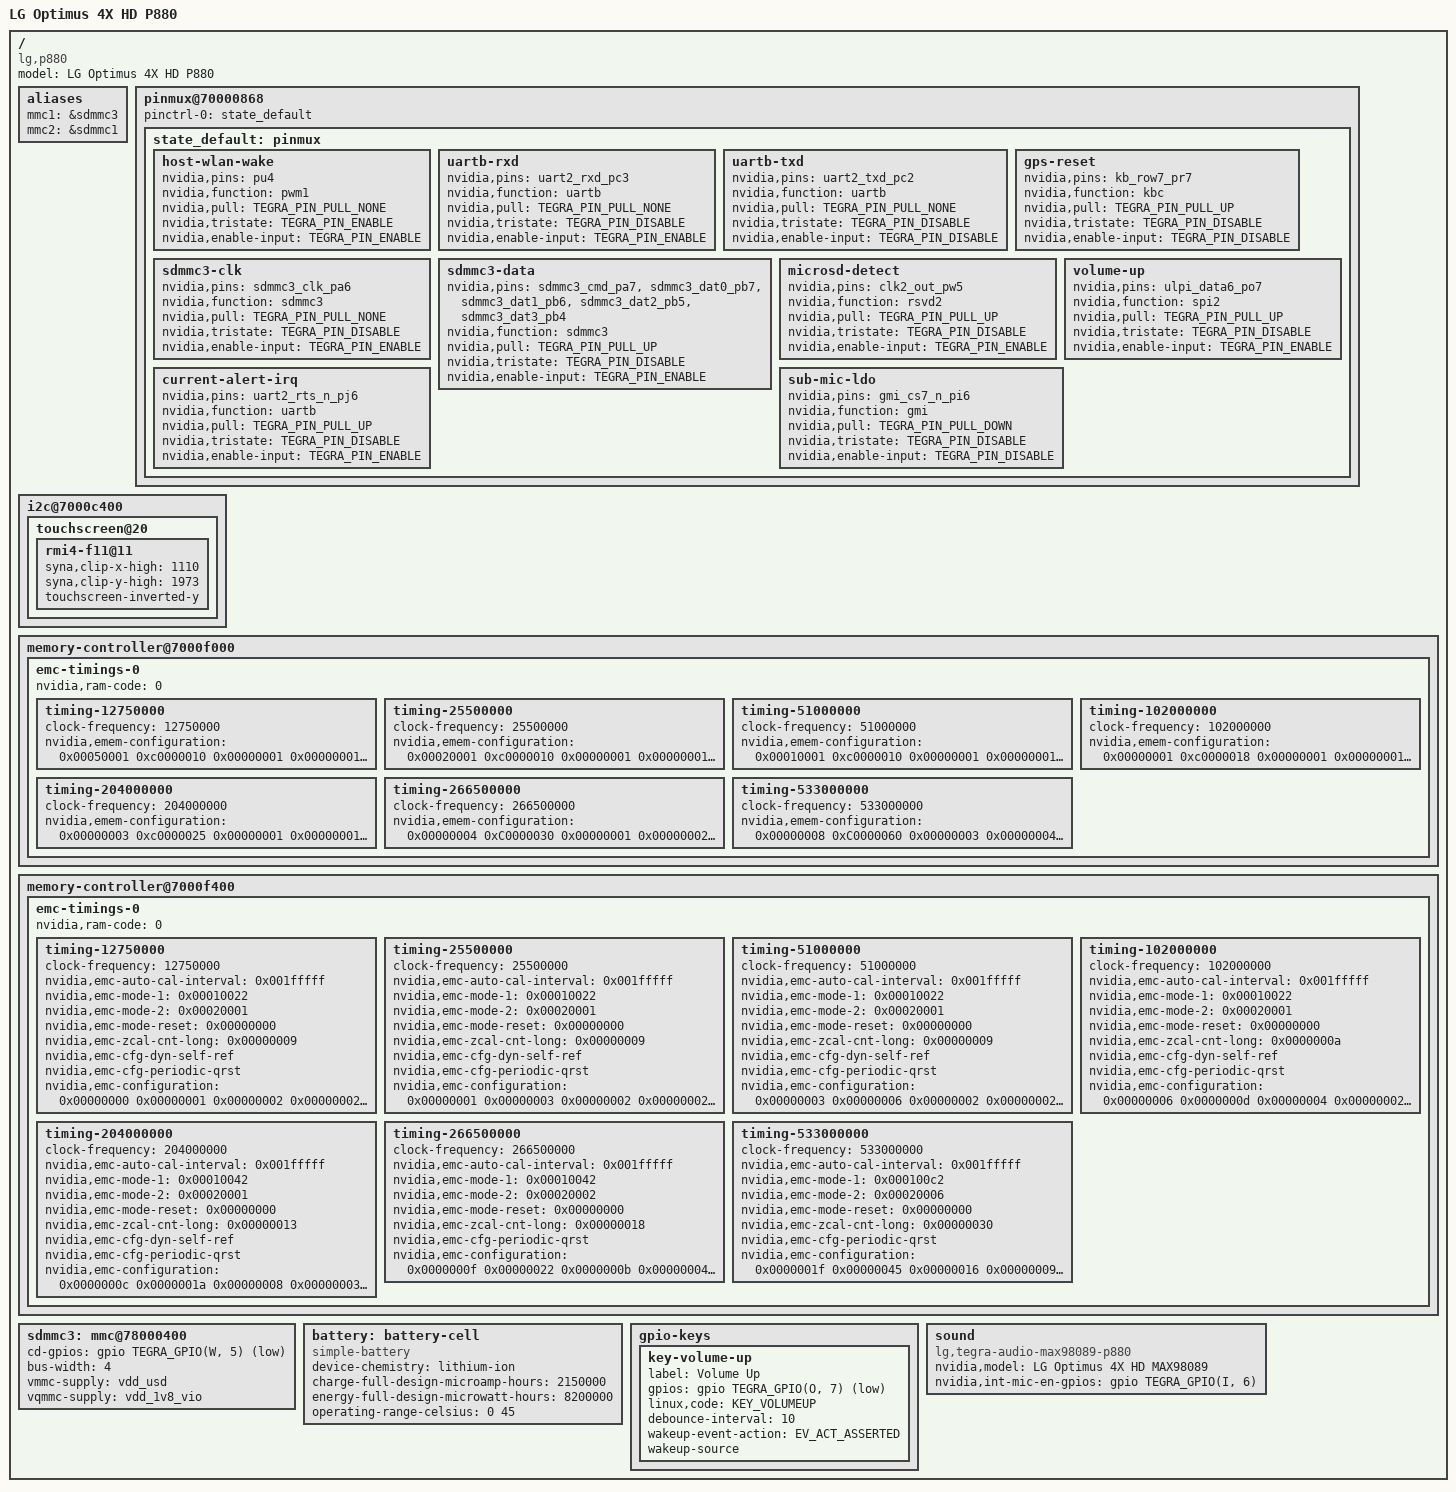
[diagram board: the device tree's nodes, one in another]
// SPDX-License-Identifier: GPL-2.0
/dts-v1/;

#include "tegra30-lg-x3.dtsi"

/ {
	model = "LG Optimus 4X HD P880";
	compatible = "lg,p880", "nvidia,tegra30";

	aliases {
		mmc1 = &sdmmc3; /* uSD slot */
		mmc2 = &sdmmc1; /* WiFi */
	};

	pinmux@70000868 {
		pinctrl-names = "default";
		pinctrl-0 = <&state_default>;

		state_default: pinmux {
			/* WLAN SDIO pinmux */
			host-wlan-wake {
				nvidia,pins = "pu4";
				nvidia,function = "pwm1";
				nvidia,pull = <TEGRA_PIN_PULL_NONE>;
				nvidia,tristate = <TEGRA_PIN_ENABLE>;
				nvidia,enable-input = <TEGRA_PIN_ENABLE>;
			};

			/* GNSS UART-B pinmux */
			uartb-rxd {
				nvidia,pins = "uart2_rxd_pc3";
				nvidia,function = "uartb";
				nvidia,pull = <TEGRA_PIN_PULL_NONE>;
				nvidia,tristate = <TEGRA_PIN_DISABLE>;
				nvidia,enable-input = <TEGRA_PIN_ENABLE>;
			};
			uartb-txd {
				nvidia,pins = "uart2_txd_pc2";
				nvidia,function = "uartb";
				nvidia,pull = <TEGRA_PIN_PULL_NONE>;
				nvidia,tristate = <TEGRA_PIN_DISABLE>;
				nvidia,enable-input = <TEGRA_PIN_DISABLE>;
			};
			gps-reset {
				nvidia,pins = "kb_row7_pr7";
				nvidia,function = "kbc";
				nvidia,pull = <TEGRA_PIN_PULL_UP>;
				nvidia,tristate = <TEGRA_PIN_DISABLE>;
				nvidia,enable-input = <TEGRA_PIN_DISABLE>;
			};

			/* MicroSD pinmux */
			sdmmc3-clk {
				nvidia,pins = "sdmmc3_clk_pa6";
				nvidia,function = "sdmmc3";
				nvidia,pull = <TEGRA_PIN_PULL_NONE>;
				nvidia,tristate = <TEGRA_PIN_DISABLE>;
				nvidia,enable-input = <TEGRA_PIN_ENABLE>;
			};
			sdmmc3-data {
				nvidia,pins = "sdmmc3_cmd_pa7",
						"sdmmc3_dat0_pb7",
						"sdmmc3_dat1_pb6",
						"sdmmc3_dat2_pb5",
						"sdmmc3_dat3_pb4";
				nvidia,function = "sdmmc3";
				nvidia,pull = <TEGRA_PIN_PULL_UP>;
				nvidia,tristate = <TEGRA_PIN_DISABLE>;
				nvidia,enable-input = <TEGRA_PIN_ENABLE>;
			};
			microsd-detect {
				nvidia,pins = "clk2_out_pw5";
				nvidia,function = "rsvd2";
				nvidia,pull = <TEGRA_PIN_PULL_UP>;
				nvidia,tristate = <TEGRA_PIN_DISABLE>;
				nvidia,enable-input = <TEGRA_PIN_ENABLE>;
			};

			/* GPIO keys pinmux */
			volume-up {
				nvidia,pins = "ulpi_data6_po7";
				nvidia,function = "spi2";
				nvidia,pull = <TEGRA_PIN_PULL_UP>;
				nvidia,tristate = <TEGRA_PIN_DISABLE>;
				nvidia,enable-input = <TEGRA_PIN_ENABLE>;
			};

			/* Sensors pinmux */
			current-alert-irq {
				nvidia,pins = "uart2_rts_n_pj6";
				nvidia,function = "uartb";
				nvidia,pull = <TEGRA_PIN_PULL_UP>;
				nvidia,tristate = <TEGRA_PIN_DISABLE>;
				nvidia,enable-input = <TEGRA_PIN_ENABLE>;
			};

			/* AUDIO pinmux */
			sub-mic-ldo {
				nvidia,pins = "gmi_cs7_n_pi6";
				nvidia,function = "gmi";
				nvidia,pull = <TEGRA_PIN_PULL_DOWN>;
				nvidia,tristate = <TEGRA_PIN_DISABLE>;
				nvidia,enable-input = <TEGRA_PIN_DISABLE>;
			};
		};
	};

	i2c@7000c400 {
		touchscreen@20 {
			rmi4-f11@11 {
				syna,clip-x-high = <1110>;
				syna,clip-y-high = <1973>;

				touchscreen-inverted-y;
			};
		};
	};

	memory-controller@7000f000 {
		emc-timings-0 {
			/* SAMSUNG 1GB K4P8G304EB FGC1 533MHz */
			nvidia,ram-code = <0>;

			timing-12750000 {
				clock-frequency = <12750000>;

				nvidia,emem-configuration = < 0x00050001 0xc0000010
					0x00000001 0x00000001 0x00000002 0x00000000
					0x00000003 0x00000001 0x00000002 0x00000004
					0x00000001 0x00000000 0x00000002 0x00000002
					0x02020001 0x00060402 0x77230303 0x001f0000 >;
			};

			timing-25500000 {
				clock-frequency = <25500000>;

				nvidia,emem-configuration = < 0x00020001 0xc0000010
					0x00000001 0x00000001 0x00000002 0x00000000
					0x00000003 0x00000001 0x00000002 0x00000004
					0x00000001 0x00000000 0x00000002 0x00000002
					0x02020001 0x00060402 0x73e30303 0x001f0000 >;
			};

			timing-51000000 {
				clock-frequency = <51000000>;

				nvidia,emem-configuration = < 0x00010001 0xc0000010
					0x00000001 0x00000001 0x00000002 0x00000000
					0x00000003 0x00000001 0x00000002 0x00000004
					0x00000001 0x00000000 0x00000002 0x00000002
					0x02020001 0x00060402 0x72c30303 0x001f0000 >;
			};

			timing-102000000 {
				clock-frequency = <102000000>;

				nvidia,emem-configuration = < 0x00000001 0xc0000018
					0x00000001 0x00000001 0x00000003 0x00000001
					0x00000003 0x00000001 0x00000002 0x00000004
					0x00000001 0x00000000 0x00000002 0x00000002
					0x02020001 0x00060403 0x72430504 0x001f0000 >;
			};

			timing-204000000 {
				clock-frequency = <204000000>;

				nvidia,emem-configuration = < 0x00000003 0xc0000025
					0x00000001 0x00000001 0x00000006 0x00000003
					0x00000005 0x00000001 0x00000002 0x00000004
					0x00000001 0x00000000 0x00000003 0x00000002
					0x02030001 0x00070506 0x71e40a07 0x001f0000 >;
			};

			timing-266500000 {
				clock-frequency = <266500000>;

				nvidia,emem-configuration = < 0x00000004 0xC0000030
					0x00000001 0x00000002 0x00000008 0x00000004
					0x00000006 0x00000001 0x00000002 0x00000005
					0x00000001 0x00000000 0x00000003 0x00000003
					0x03030001 0x00090608 0x70040c09 0x001f0000 >;
			};

			timing-533000000 {
				clock-frequency = <533000000>;

				nvidia,emem-configuration = < 0x00000008 0xC0000060
					0x00000003 0x00000004 0x00000010 0x0000000a
					0x0000000d 0x00000002 0x00000002 0x00000008
					0x00000002 0x00000000 0x00000004 0x00000005
					0x05040002 0x00110b10 0x70281811 0x001f0000 >;
			};
		};
	};

	memory-controller@7000f400 {
		emc-timings-0 {
			/* SAMSUNG 1GB K4P8G304EB FGC1 533MHz */
			nvidia,ram-code = <0>;

			timing-12750000 {
				clock-frequency = <12750000>;

				nvidia,emc-auto-cal-interval = <0x001fffff>;
				nvidia,emc-mode-1 = <0x00010022>;
				nvidia,emc-mode-2 = <0x00020001>;
				nvidia,emc-mode-reset = <0x00000000>;
				nvidia,emc-zcal-cnt-long = <0x00000009>;
				nvidia,emc-cfg-dyn-self-ref;
				nvidia,emc-cfg-periodic-qrst;

				nvidia,emc-configuration =  < 0x00000000
					0x00000001 0x00000002 0x00000002 0x00000004
					0x00000004 0x00000001 0x00000005 0x00000002
					0x00000002 0x00000001 0x00000001 0x00000000
					0x00000001 0x00000003 0x00000001 0x0000000b
					0x00000009 0x0000002f 0x00000000 0x0000000b
					0x00000001 0x00000001 0x00000002 0x00000000
					0x00000001 0x00000007 0x00000002 0x00000002
					0x00000003 0x00000008 0x00000004 0x00000001
					0x00000002 0x00000036 0x00000004 0x00000004
					0x00000000 0x00000000 0x00004282 0x007800a4
					0x00008000 0x000fc000 0x000fc000 0x000fc000
					0x000fc000 0x000fc000 0x000fc000 0x000fc000
					0x000fc000 0x00000000 0x00000000 0x00000000
					0x00000000 0x00000000 0x00000000 0x00000000
					0x00000000 0x00000000 0x00000000 0x00000000
					0x00000000 0x00000000 0x00000000 0x00000000
					0x00000000 0x000fc000 0x000fc000 0x000fc000
					0x000fc000 0x00100220 0x0800201c 0x00000000
					0x77ffc004 0x01f1f008 0x00000000 0x00000007
					0x08000068 0x08000000 0x00000802 0x00064000
					0x00000009 0x00090009 0xa0f10000 0x00000000
					0x00000000 0x80000164 0xe0000000 0xff00ff00 >;
			};

			timing-25500000 {
				clock-frequency = <25500000>;

				nvidia,emc-auto-cal-interval = <0x001fffff>;
				nvidia,emc-mode-1 = <0x00010022>;
				nvidia,emc-mode-2 = <0x00020001>;
				nvidia,emc-mode-reset = <0x00000000>;
				nvidia,emc-zcal-cnt-long = <0x00000009>;
				nvidia,emc-cfg-dyn-self-ref;
				nvidia,emc-cfg-periodic-qrst;

				nvidia,emc-configuration =  < 0x00000001
					0x00000003 0x00000002 0x00000002 0x00000004
					0x00000004 0x00000001 0x00000005 0x00000002
					0x00000002 0x00000001 0x00000001 0x00000000
					0x00000001 0x00000003 0x00000001 0x0000000b
					0x00000009 0x00000060 0x00000000 0x00000018
					0x00000001 0x00000001 0x00000002 0x00000000
					0x00000001 0x00000007 0x00000004 0x00000004
					0x00000003 0x00000008 0x00000004 0x00000001
					0x00000002 0x0000006b 0x00000004 0x00000004
					0x00000000 0x00000000 0x00004282 0x007800a4
					0x00008000 0x000fc000 0x000fc000 0x000fc000
					0x000fc000 0x000fc000 0x000fc000 0x000fc000
					0x000fc000 0x00000000 0x00000000 0x00000000
					0x00000000 0x00000000 0x00000000 0x00000000
					0x00000000 0x00000000 0x00000000 0x00000000
					0x00000000 0x00000000 0x00000000 0x00000000
					0x00000000 0x000fc000 0x000fc000 0x000fc000
					0x000fc000 0x00100220 0x0800201c 0x00000000
					0x77ffc004 0x01f1f008 0x00000000 0x00000007
					0x08000068 0x08000000 0x00000802 0x00064000
					0x0000000a 0x00090009 0xa0f10000 0x00000000
					0x00000000 0x800001c5 0xe0000000 0xff00ff00 >;
			};

			timing-51000000 {
				clock-frequency = <51000000>;

				nvidia,emc-auto-cal-interval = <0x001fffff>;
				nvidia,emc-mode-1 = <0x00010022>;
				nvidia,emc-mode-2 = <0x00020001>;
				nvidia,emc-mode-reset = <0x00000000>;
				nvidia,emc-zcal-cnt-long = <0x00000009>;
				nvidia,emc-cfg-dyn-self-ref;
				nvidia,emc-cfg-periodic-qrst;

				nvidia,emc-configuration =  < 0x00000003
					0x00000006 0x00000002 0x00000002 0x00000004
					0x00000004 0x00000001 0x00000005 0x00000002
					0x00000002 0x00000001 0x00000001 0x00000000
					0x00000001 0x00000003 0x00000001 0x0000000b
					0x00000009 0x000000c0 0x00000000 0x00000030
					0x00000001 0x00000001 0x00000002 0x00000000
					0x00000001 0x00000007 0x00000008 0x00000008
					0x00000003 0x00000008 0x00000004 0x00000001
					0x00000002 0x000000d5 0x00000004 0x00000004
					0x00000000 0x00000000 0x00004282 0x007800a4
					0x00008000 0x000fc000 0x000fc000 0x000fc000
					0x000fc000 0x000fc000 0x000fc000 0x000fc000
					0x000fc000 0x00000000 0x00000000 0x00000000
					0x00000000 0x00000000 0x00000000 0x00000000
					0x00000000 0x00000000 0x00000000 0x00000000
					0x00000000 0x00000000 0x00000000 0x00000000
					0x00000000 0x000fc000 0x000fc000 0x000fc000
					0x000fc000 0x00100220 0x0800201c 0x00000000
					0x77ffc004 0x01f1f008 0x00000000 0x00000007
					0x08000068 0x08000000 0x00000802 0x00064000
					0x00000013 0x00090009 0xa0f10000 0x00000000
					0x00000000 0x80000287 0xe0000000 0xff00ff00 >;
			};

			timing-102000000 {
				clock-frequency = <102000000>;

				nvidia,emc-auto-cal-interval = <0x001fffff>;
				nvidia,emc-mode-1 = <0x00010022>;
				nvidia,emc-mode-2 = <0x00020001>;
				nvidia,emc-mode-reset = <0x00000000>;
				nvidia,emc-zcal-cnt-long = <0x0000000a>;
				nvidia,emc-cfg-dyn-self-ref;
				nvidia,emc-cfg-periodic-qrst;

				nvidia,emc-configuration =  < 0x00000006
					0x0000000d 0x00000004 0x00000002 0x00000004
					0x00000004 0x00000001 0x00000005 0x00000002
					0x00000002 0x00000001 0x00000001 0x00000000
					0x00000001 0x00000003 0x00000001 0x0000000b
					0x00000009 0x00000181 0x00000000 0x00000060
					0x00000001 0x00000001 0x00000002 0x00000000
					0x00000001 0x00000007 0x0000000f 0x0000000f
					0x00000003 0x00000008 0x00000004 0x00000001
					0x00000002 0x000001a9 0x00000004 0x00000004
					0x00000000 0x00000000 0x00004282 0x007800a4
					0x00008000 0x000fc000 0x000fc000 0x000fc000
					0x000fc000 0x000fc000 0x000fc000 0x000fc000
					0x000fc000 0x00000000 0x00000000 0x00000000
					0x00000000 0x00000000 0x00000000 0x00000000
					0x00000000 0x00000000 0x00000000 0x00000000
					0x00000000 0x00000000 0x00000000 0x00000000
					0x00000000 0x000fc000 0x000fc000 0x000fc000
					0x000fc000 0x00100220 0x0800201c 0x00000000
					0x77ffc004 0x01f1f008 0x00000000 0x00000007
					0x08000068 0x08000000 0x00000802 0x00064000
					0x00000025 0x00090009 0xa0f10000 0x00000000
					0x00000000 0x8000040b 0xe0000000 0xff00ff00 >;
			};

			timing-204000000 {
				clock-frequency = <204000000>;

				nvidia,emc-auto-cal-interval = <0x001fffff>;
				nvidia,emc-mode-1 = <0x00010042>;
				nvidia,emc-mode-2 = <0x00020001>;
				nvidia,emc-mode-reset = <0x00000000>;
				nvidia,emc-zcal-cnt-long = <0x00000013>;
				nvidia,emc-cfg-dyn-self-ref;
				nvidia,emc-cfg-periodic-qrst;

				nvidia,emc-configuration =  < 0x0000000c
					0x0000001a 0x00000008 0x00000003 0x00000005
					0x00000004 0x00000001 0x00000006 0x00000003
					0x00000003 0x00000002 0x00000002 0x00000000
					0x00000001 0x00000003 0x00000001 0x0000000c
					0x0000000a 0x00000303 0x00000000 0x000000c0
					0x00000001 0x00000001 0x00000003 0x00000000
					0x00000001 0x00000007 0x0000001d 0x0000001d
					0x00000004 0x0000000b 0x00000005 0x00000001
					0x00000002 0x00000351 0x00000004 0x00000006
					0x00000000 0x00000000 0x00004282 0x004400a4
					0x00008000 0x00070000 0x00070000 0x00070000
					0x00070000 0x00070000 0x00070000 0x00070000
					0x00070000 0x00000000 0x00000000 0x00000000
					0x00000000 0x00000000 0x00000000 0x00000000
					0x00000000 0x00000000 0x00000000 0x00000000
					0x00000000 0x00000000 0x00000000 0x00000000
					0x00000000 0x00080000 0x00080000 0x00080000
					0x00080000 0x000e0220 0x0800201c 0x00000000
					0x77ffc004 0x01f1f008 0x00000000 0x00000007
					0x08000068 0x08000000 0x00000802 0x00064000
					0x0000004a 0x00090009 0xa0f10000 0x00000000
					0x00000000 0x80000713 0xe0000000 0xff00ff00 >;
			};

			timing-266500000 {
				clock-frequency = <266500000>;

				nvidia,emc-auto-cal-interval = <0x001fffff>;
				nvidia,emc-mode-1 = <0x00010042>;
				nvidia,emc-mode-2 = <0x00020002>;
				nvidia,emc-mode-reset = <0x00000000>;
				nvidia,emc-zcal-cnt-long = <0x00000018>;
				nvidia,emc-cfg-periodic-qrst;

				nvidia,emc-configuration =  < 0x0000000f
					0x00000022 0x0000000b 0x00000004 0x00000005
					0x00000005 0x00000001 0x00000007 0x00000004
					0x00000004 0x00000002 0x00000002 0x00000000
					0x00000002 0x00000005 0x00000002 0x0000000c
					0x0000000b 0x000003ef 0x00000000 0x000000fb
					0x00000001 0x00000001 0x00000004 0x00000000
					0x00000001 0x00000009 0x00000026 0x00000026
					0x00000004 0x0000000e 0x00000006 0x00000001
					0x00000002 0x00000455 0x00000000 0x00000004
					0x00000000 0x00000000 0x00006282 0x003200a4
					0x00008000 0x00050000 0x00050000 0x00050000
					0x00050000 0x00050000 0x00050000 0x00050000
					0x00050000 0x00000000 0x00000000 0x00000000
					0x00000000 0x00000000 0x00000000 0x00000000
					0x00000000 0x00000000 0x00000000 0x00000000
					0x00000000 0x00000000 0x00000000 0x00000000
					0x00000000 0x00060000 0x00060000 0x00060000
					0x00060000 0x000b0220 0x0800003d 0x00000000
					0x77ffc004 0x01f1f008 0x00000000 0x00000007
					0x08000068 0x08000000 0x00000802 0x00064000
					0x00000060 0x000a000a 0xa0f10000 0x00000000
					0x00000000 0x800008ee 0xe0000000 0xff00ff00 >;
			};

			timing-533000000 {
				clock-frequency = <533000000>;

				nvidia,emc-auto-cal-interval = <0x001fffff>;
				nvidia,emc-mode-1 = <0x000100c2>;
				nvidia,emc-mode-2 = <0x00020006>;
				nvidia,emc-mode-reset = <0x00000000>;
				nvidia,emc-zcal-cnt-long = <0x00000030>;
				nvidia,emc-cfg-periodic-qrst;

				nvidia,emc-configuration =  < 0x0000001f
					0x00000045 0x00000016 0x00000009 0x00000008
					0x00000009 0x00000003 0x0000000d 0x00000009
					0x00000009 0x00000005 0x00000003 0x00000000
					0x00000004 0x00000009 0x00000006 0x0000000d
					0x00000010 0x000007df 0x00000000 0x000001f7
					0x00000003 0x00000003 0x00000009 0x00000000
					0x00000001 0x0000000f 0x0000004b 0x0000004b
					0x00000008 0x0000001b 0x0000000c 0x00000001
					0x00000002 0x000008aa 0x00000000 0x00000006
					0x00000000 0x00000000 0x00006282 0xf0120091
					0x00008000 0x0000000a 0x0000000a 0x0000000a
					0x0000000a 0x0000000a 0x0000000a 0x0000000a
					0x0000000a 0x00000000 0x00000000 0x00000000
					0x00000000 0x00000000 0x00000000 0x00000000
					0x00000000 0x00000000 0x00000000 0x00000000
					0x00000000 0x00000000 0x00000000 0x00000000
					0x00000000 0x0000000a 0x0000000a 0x0000000a
					0x0000000a 0x00090220 0x0800003d 0x00000000
					0x77ffc004 0x01f1f408 0x00000000 0x00000007
					0x08000068 0x08000000 0x00000802 0x00064000
					0x000000c0 0x000e000e 0xa0f10000 0x00000000
					0x00000000 0x800010d9 0xe0000000 0xff00ff88 >;
			};
		};
	};

	sdmmc3: mmc@78000400 {
		status = "okay";

		cd-gpios = <&gpio TEGRA_GPIO(W, 5) GPIO_ACTIVE_LOW>;
		bus-width = <4>;

		vmmc-supply = <&vdd_usd>;
		vqmmc-supply = <&vdd_1v8_vio>;
	};

	battery: battery-cell {
		compatible = "simple-battery";
		device-chemistry = "lithium-ion";
		charge-full-design-microamp-hours = <2150000>;
		energy-full-design-microwatt-hours = <8200000>;
		operating-range-celsius = <0 45>;
	};

	gpio-keys {
		key-volume-up {
			label = "Volume Up";
			gpios = <&gpio TEGRA_GPIO(O, 7) GPIO_ACTIVE_LOW>;
			linux,code = <KEY_VOLUMEUP>;
			debounce-interval = <10>;
			wakeup-event-action = <EV_ACT_ASSERTED>;
			wakeup-source;
		};
	};

	sound {
		compatible = "lg,tegra-audio-max98089-p880",
			     "nvidia,tegra-audio-max98089";
		nvidia,model = "LG Optimus 4X HD MAX98089";

		nvidia,int-mic-en-gpios = <&gpio TEGRA_GPIO(I, 6) GPIO_ACTIVE_HIGH>;
	};
};
